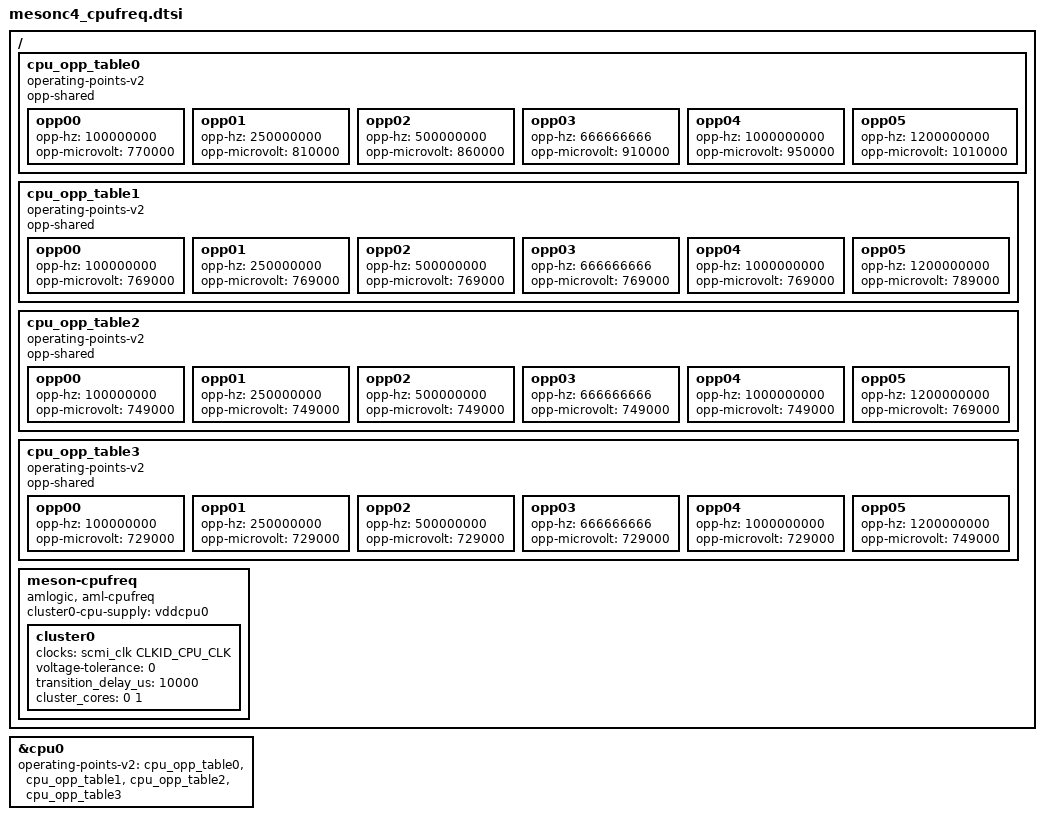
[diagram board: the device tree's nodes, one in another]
// SPDX-License-Identifier: (GPL-2.0+ OR MIT)
/*
 * Copyright (c) 2019 Amlogic, Inc. All rights reserved.
 */

/ {
		cpu_opp_table0: cpu_opp_table0 {
		compatible = "operating-points-v2";
		opp-shared;

		opp00 {
			opp-hz = /bits/ 64 <100000000>;
			opp-microvolt = <770000>;
		};
		opp01 {
			opp-hz = /bits/ 64 <250000000>;
			opp-microvolt = <810000>;
		};
		opp02 {
			opp-hz = /bits/ 64 <500000000>;
			opp-microvolt = <860000>;
		};
		opp03 {
			opp-hz = /bits/ 64 <666666666>;
			opp-microvolt = <910000>;
		};
		opp04 {
			opp-hz = /bits/ 64 <1000000000>;
			opp-microvolt = <950000>;
		};
		opp05 {
			opp-hz = /bits/ 64 <1200000000>;
			opp-microvolt = <1010000>;
		};
	};

	cpu_opp_table1: cpu_opp_table1 {
		compatible = "operating-points-v2";
		opp-shared;

		opp00 {
			opp-hz = /bits/ 64 <100000000>;
			opp-microvolt = <769000>;
		};
		opp01 {
			opp-hz = /bits/ 64 <250000000>;
			opp-microvolt = <769000>;
		};
		opp02 {
			opp-hz = /bits/ 64 <500000000>;
			opp-microvolt = <769000>;
		};
		opp03 {
			opp-hz = /bits/ 64 <666666666>;
			opp-microvolt = <769000>;
		};
		opp04 {
			opp-hz = /bits/ 64 <1000000000>;
			opp-microvolt = <769000>;
		};
		opp05 {
			opp-hz = /bits/ 64 <1200000000>;
			opp-microvolt = <789000>;
		};
	};

	cpu_opp_table2: cpu_opp_table2 {
		compatible = "operating-points-v2";
		opp-shared;

		opp00 {
			opp-hz = /bits/ 64 <100000000>;
			opp-microvolt = <749000>;
		};
		opp01 {
			opp-hz = /bits/ 64 <250000000>;
			opp-microvolt = <749000>;
		};
		opp02 {
			opp-hz = /bits/ 64 <500000000>;
			opp-microvolt = <749000>;
		};
		opp03 {
			opp-hz = /bits/ 64 <666666666>;
			opp-microvolt = <749000>;
		};
		opp04 {
			opp-hz = /bits/ 64 <1000000000>;
			opp-microvolt = <749000>;
		};
		opp05 {
			opp-hz = /bits/ 64 <1200000000>;
			opp-microvolt = <769000>;
		};
	};

	cpu_opp_table3: cpu_opp_table3 {
		compatible = "operating-points-v2";
		opp-shared;

		opp00 {
			opp-hz = /bits/ 64 <100000000>;
			opp-microvolt = <729000>;
		};
		opp01 {
			opp-hz = /bits/ 64 <250000000>;
			opp-microvolt = <729000>;
		};
		opp02 {
			opp-hz = /bits/ 64 <500000000>;
			opp-microvolt = <729000>;
		};
		opp03 {
			opp-hz = /bits/ 64 <666666666>;
			opp-microvolt = <729000>;
		};
		opp04 {
			opp-hz = /bits/ 64 <1000000000>;
			opp-microvolt = <729000>;
		};
		opp05 {
			opp-hz = /bits/ 64 <1200000000>;
			opp-microvolt = <749000>;
		};
	};

	meson-cpufreq {
		compatible = "amlogic, aml-cpufreq";
		status = "okay";

		cluster0-cpu-supply = <&vddcpu0>;

		cluster0 {
			clocks = <&scmi_clk CLKID_CPU_CLK>;
			clock-names = "cpuclk";
			voltage-tolerance = <0>;
			transition_delay_us = <10000>;
			//skip_volt_scaling;
			cluster_cores = <0 1>;
			//pdvfs_enabled;
		};
	};
};/* end of / */

&cpu0 {
	operating-points-v2 = <&cpu_opp_table0>,
				<&cpu_opp_table1>,
				<&cpu_opp_table2>,
				<&cpu_opp_table3>;
};
